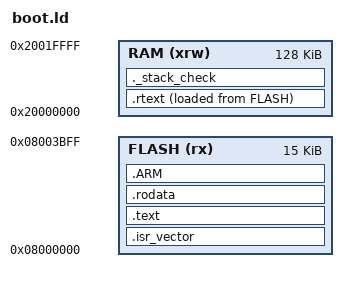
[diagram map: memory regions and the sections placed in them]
/* Entry Point */
ENTRY(main)

/* Highest address of the user mode stack */
_estack = 0x20020000;    /* end of RAM */
/* Generate a link error if heap and stack don't fit into RAM */
_Min_Stack_Size = 0x400; /* required amount of stack */

/* Specify the memory areas */
MEMORY
{
RAM (xrw)      : ORIGIN = 0x20000000, LENGTH = 128K
FLASH (rx)      : ORIGIN = 0x8000000, LENGTH = 15K
}

/* Define output sections */
SECTIONS
{
  /* The startup code goes first into FLASH */
  .isr_vector :
  {
    . = ALIGN(4);
    KEEP(*(.isr_vector)) /* Startup code */
    . = ALIGN(4);
  } >FLASH

  /* The program code and other data goes into FLASH */
  .text :
  {
    . = ALIGN(4);
    *(.text)           /* .text sections (code) */
    *(.text*)          /* .text* sections (code) */
    *(.glue_7)         /* glue arm to thumb code */
    *(.glue_7t)        /* glue thumb to arm code */

    KEEP (*(.init))
    KEEP (*(.fini))

    . = ALIGN(4);
    _etext = .;        /* define a global symbols at end of code */
  } >FLASH

  .rtext :
  {
	  . = ALIGN(4);
	  _srtext = .;
	  *(.rtext)
	  *(.rtext*)
	  . = ALIGN(4);
	  _ertext = .;
  } >RAM AT> FLASH

  _sirtext = LOADADDR(.rtext);

  /* Constant data goes into FLASH */
  .rodata :
  {
    . = ALIGN(4);
    *(.rodata)         /* .rodata sections (constants, strings, etc.) */
    *(.rodata*)        /* .rodata* sections (constants, strings, etc.) */
    . = ALIGN(4);
  } >FLASH

  .ARM : {
    __exidx_start = .;
    __exidx_end = .;
  } >FLASH

  /* User_heap_stack section, used to check that there is enough RAM left */
  ._stack_check :
  {
    . = ALIGN(4);
    PROVIDE ( end = . );
    PROVIDE ( _end = . );
    . = . + _Min_Stack_Size;
    . = ALIGN(4);
  } >RAM

  /DISCARD/ :
  {
	*(.ARM.ex*)
  }

  .ARM.attributes 0 : { *(.ARM.attributes) }
}


